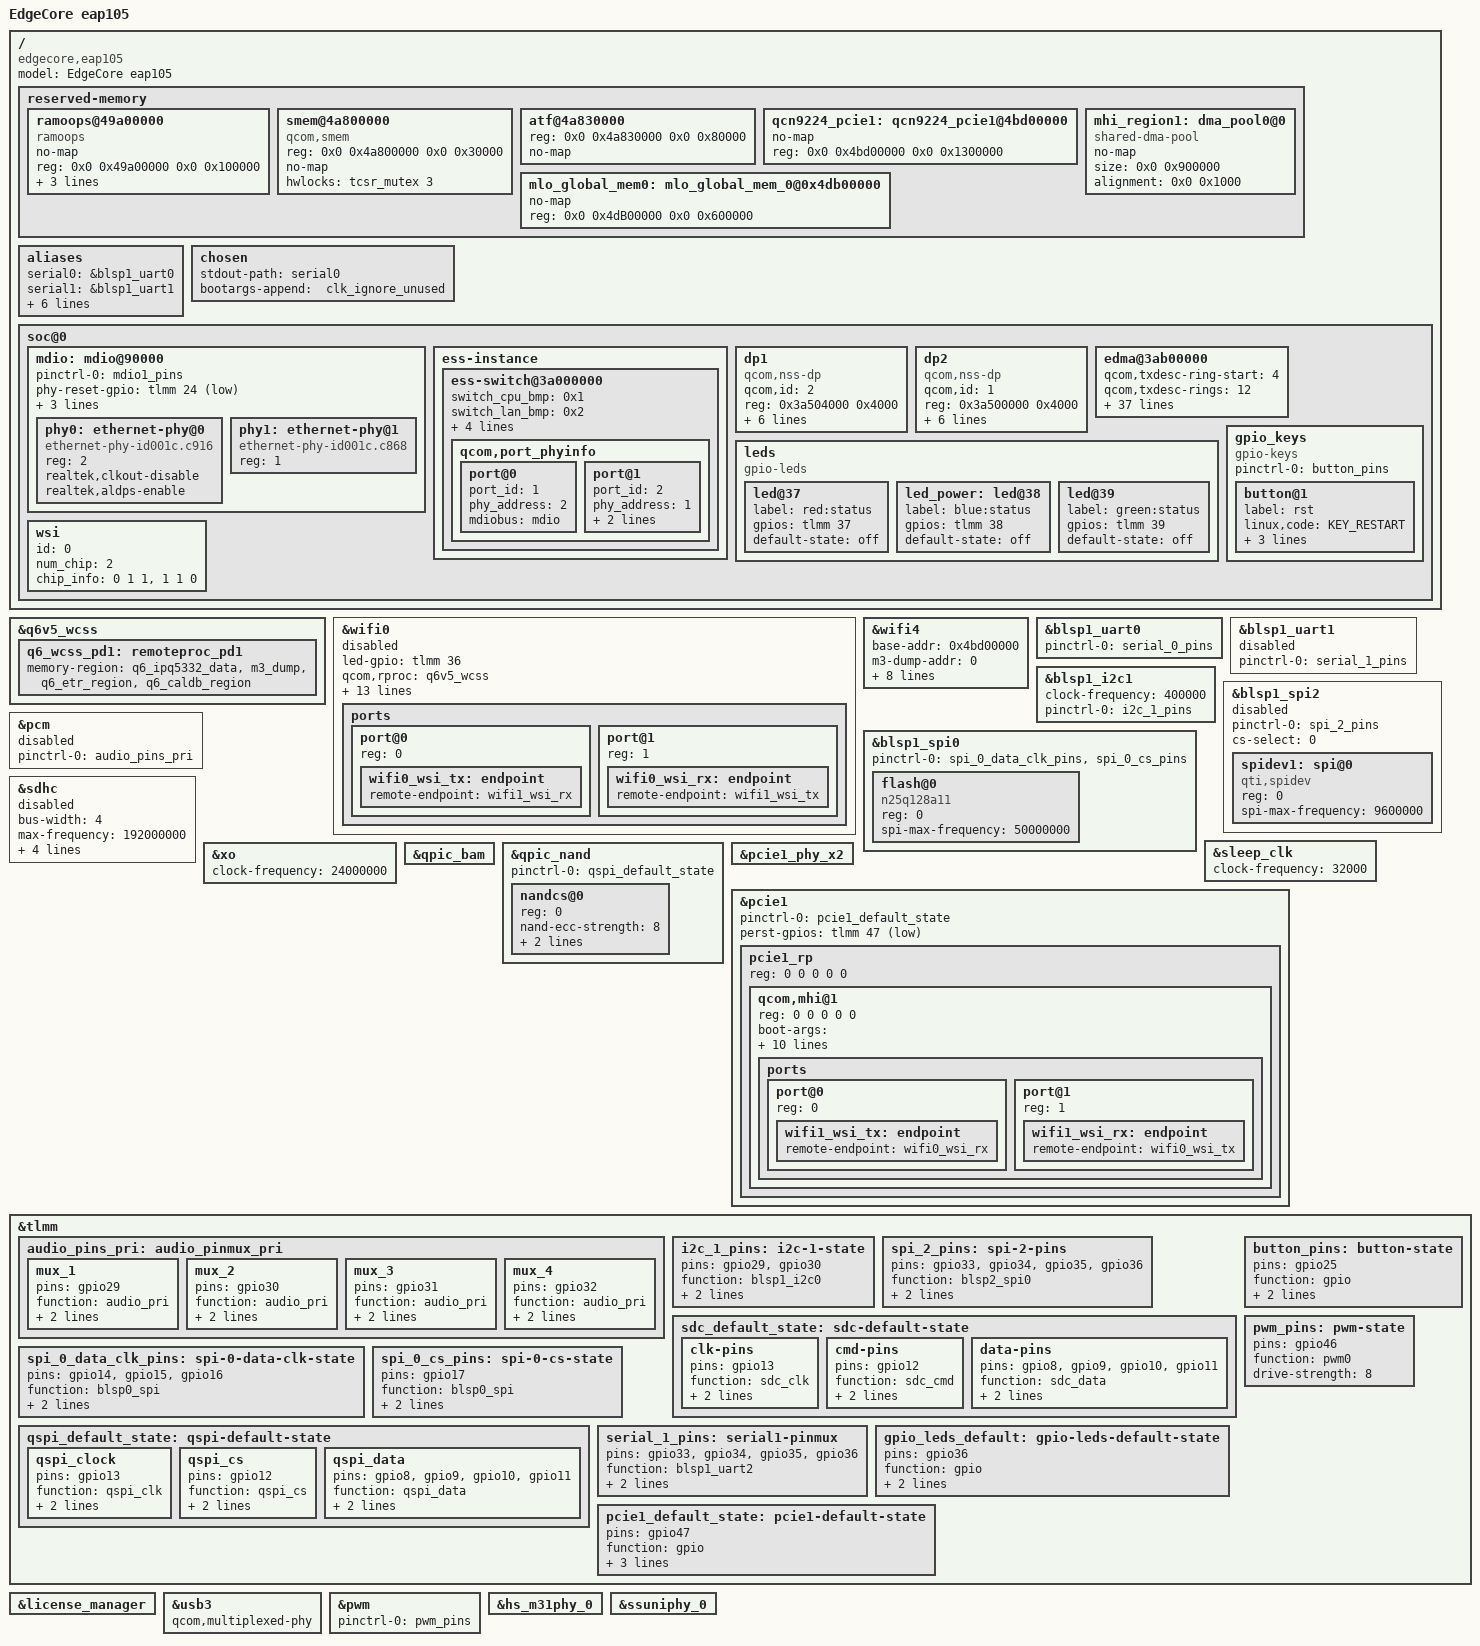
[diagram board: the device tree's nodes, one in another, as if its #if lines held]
// SPDX-License-Identifier: (GPL-2.0+ OR BSD-3-Clause)
/*
 * IPQ5332 RDP468 board device tree source
 *
 * Copyright (c) 2020-2021 The Linux Foundation. All rights reserved.
 * Copyright (c) 2022-2025 Qualcomm Innovation Center, Inc. All rights reserved.
 */

/dts-v1/;

#define __RPROC_DISABLE_MPD_SUPPORT__

#include <dt-bindings/gpio/gpio.h>
#include <dt-bindings/input/input.h>
#include <dt-bindings/leds/common.h>
#include "ipq5332.dtsi"
#include "ipq5332-default-memory.dtsi"

/ {
	model = "EdgeCore eap105";
	compatible = "edgecore,eap105", "qcom,ipq5332-ap-mi01.6", "qcom,ipq5332";

	reserved-memory {
		#address-cells = <2>;
		#size-cells = <2>;
		ranges;

		ramoops@49a00000 {
			compatible = "ramoops";
			no-map;
			reg = <0x0 0x49a00000 0x0 0x100000>;
			record-size = <0x50000>;
			console-size = <0x50000>;
			pmsg-size = <0x50000>;
		};
	};

	aliases {
		serial0 = &blsp1_uart0;
		serial1 = &blsp1_uart1;
		ethernet0 = "/soc/dp1";
		ethernet1 = "/soc/dp2";
		led-boot = &led_power;
		led-failsafe = &led_power;
		led-running = &led_power;
		led-upgrade = &led_power;
	};

	chosen {
		stdout-path = "serial0";
		bootargs-append = " clk_ignore_unused";
	};

#if defined(__IPQ_MEM_PROFILE_256_MB__)
	/*	  256MB Profile for IPQ5322 + QCN9224
	 * +=========+==============+========================+
	 * |        |              |                         |
	 * | Region | Start Offset |          Size           |
	 * |        |              |                         |
	 * +--------+--------------+-------------------------+
	 * |  SMEM  |  0x4A800000  |          192KB          |
	 * +--------+--------------+-------------------------+
	 * |  ATF   |  0x4A830000  |          512KB          |
	 * +--------+--------------+-------------------------+
	 * |       320 KB not-reserved, used by linux        |
	 * +--------+--------------+-------------------------+
	 * |  WKK0  |  0x4BD00000  |          19MB           |
	 * +--------+--------------+-------------------------+
	 * |       11 MB not-reserved, used by linux         |
	 * +--------+--------------+-------------------------+
	 * |  MLO   |  0x4DB00000  |           5MB           |
	 * +--------+--------------+-------------------------+
	 * |  MHI0  |    DYNAMIC   |           9MB           |
	 * +=================================================+
	 * |                                                 |
	 * |                                                 |
	 * |            Rest of memory for Linux             |
	 * |                                                 |
	 * |                                                 |
	 * +=================================================+
	 */

	reserved-memory {
		/delete-node/ bootloader@4a300000;
		/delete-node/ sbl@4a500000;

		smem@4a800000 {
			compatible = "qcom,smem";
			reg = <0x0 0x4a800000 0x0 0x30000>;
			no-map;
			hwlocks = <&tcsr_mutex 3>;
		};

		atf@4a830000 {
			reg = <0x0 0x4a830000 0x0 0x80000>;
			no-map;
		};

		qcn9224_pcie1: qcn9224_pcie1@4bd00000 {
			no-map;
			reg = <0x0 0x4bd00000 0x0 0x1300000>;
		};

		mlo_global_mem0: mlo_global_mem_0@0x4db00000 {
			no-map;
			reg = <0x0 0x4dB00000 0x0 0x600000>;
		};

		mhi_region1: dma_pool0@0 {
			compatible = "shared-dma-pool";
			no-map;
			size = <0x0 0x900000>;
			alignment = <0x0 0x1000>;
		};
	};
#endif

	soc@0 {
		mdio:mdio@90000 {
			pinctrl-0 = <&mdio1_pins>;
			pinctrl-names = "default";
			phy-reset-gpio = <&tlmm 24 GPIO_ACTIVE_LOW>;
			phyaddr_fixup = <0xC90F018>;
			uniphyaddr_fixup = <0xC90F014>;
			mdio_clk_fixup; /* MDIO clock sequence fix up flag */
			status = "okay";

			phy0: ethernet-phy@0 {
				reg = <2>;
				compatible = "ethernet-phy-id001c.c916";
				realtek,clkout-disable;
				realtek,aldps-enable;
			};

			phy1: ethernet-phy@1 {
				reg = <1>;
				compatible = "ethernet-phy-id001c.c868";
			};
		};

		ess-instance {
			ess-switch@3a000000 {
				switch_cpu_bmp = <0x1>;  /* cpu port bitmap */
				switch_lan_bmp = <0x2>; /* lan port bitmap */
				switch_wan_bmp = <0x4>; /* wan port bitmap */
				switch_mac_mode = <0xf>; /* mac mode for uniphy instance0*/
				switch_mac_mode1 = <0xd>; /* mac mode for uniphy instance1*/
				switch_mac_mode2 = <0xff>; /* mac mode for uniphy instance2*/

				qcom,port_phyinfo {
					port@0 {
						port_id = <1>;
						phy_address = <2>;
						mdiobus = <&mdio>;
					};
					port@1 {
						port_id = <2>;
						phy_address = <1>;
						mdiobus = <&mdio>;
						ethernet-phy-ieee802.3-c45;
					};
				};
			};
		};

		dp1 {
			device_type = "network";
			compatible = "qcom,nss-dp";
			qcom,id = <2>;
			reg = <0x3a504000 0x4000>;
			qcom,mactype = <1>;
			local-mac-address = [000000000000];
			mdio-bus = <&mdio>;
			qcom,phy-mdio-addr = <1>;
			qcom,link-poll = <1>;
			phy-mode = "sgmii";
		};

		dp2 {
			device_type = "network";
			compatible = "qcom,nss-dp";
			qcom,id = <1>;
			reg = <0x3a500000 0x4000>;
			qcom,mactype = <0>;
			local-mac-address = [000000000000];
			mdio-bus = <&mdio>;
			qcom,phy-mdio-addr = <2>;
			qcom,link-poll = <1>;
			phy-mode = "sgmii";
		};

		/* EDMA host driver configuration for the board */
		edma@3ab00000 {
			qcom,txdesc-ring-start = <4>;		/* Tx desc ring start ID */
			qcom,txdesc-rings = <12>;		/* Total number of Tx desc rings to be provisioned */
			qcom,mht-txdesc-rings = <8>;            /* Extra Tx desc rings to be provisioned for MHT SW ports */
			qcom,txcmpl-ring-start = <4>;		/* Tx complete ring start ID */
			qcom,txcmpl-rings = <12>;		/* Total number of Tx complete rings to be provisioned */
			qcom,mht-txcmpl-rings = <8>;            /* Extra Tx complete rings to be provisioned for mht sw ports. */
			qcom,rxfill-ring-start = <4>;		/* Rx fill ring start ID */
			qcom,rxfill-rings = <4>;		/* Total number of Rx fill rings to be provisioned */
			qcom,rxdesc-ring-start = <12>;		/* Rx desc ring start ID */
			qcom,rxdesc-rings = <4>;		/* Total number of Rx desc rings to be provisioned */
			qcom,rx-page-mode = <0>;		/* Rx fill ring page mode */
			qcom,tx-map-priority-level = <1>;	/* Tx priority level per port */
			qcom,rx-map-priority-level = <1>;	/* Rx priority level per core */
			qcom,num_loopback_rings = <1>;
			qcom,txdesc_loopback_ring_id = <0>;
			qcom,txcmpl_loopback_ring_id = <0>;
			qcom,rxfill_loopback_ring_id = <0>;
			qcom,rxdesc_loopback_ring_id = <0>;
			qcom,loopback_queue_base = <56>;
			qcom,loopback_num_queues = <8>;
			qcom,ppeds-num = <2>;			/* Number of PPEDS nodes */
			/* PPE-DS node format: <Rx-fill Tx-cmpl Rx Tx Queue-base Queue-count> */
			qcom,ppeds-map = <1 1 1 1 32 8>,	/* PPEDS Node#0 ring and queue map */
					<2 2 2 2 40 8>;		/* PPEDS Node#1 ring and queue map */
			qcom,txdesc-map = <8 9 10 11>,		/* Port0 per-core Tx ring map */
					<12 13 14 15>,        /* MHT-Port1 per-core Tx ring map */
					<4 5 6 7>,            /* MHT-Port2 per-core Tx ring map/packets from  vp*/
					<16 17 18 19>,        /* MHT-Port3 per-core Tx ring map */
					<20 21 22 23>;        /* MHT-Port4 per-core Tx ring map */
			qcom,txdesc-fc-grp-map = <1 2 3 4 5>;   /* Per GMAC flow control group map */
			qcom,rxfill-map = <4 5 6 7>;		/* Per-core Rx fill ring map */
			qcom,rxdesc-map = <12 13 14 15>;	/* Per-core Rx desc ring map */
			qcom,rx-queue-start = <0>;		/* Rx queue start */
			qcom,rx-ring-queue-map = <0 8 16 24>,	/* Priority 0 queues per-core Rx ring map */
						<1 9 17 25>,	/* Priority 1 queues per-core Rx ring map */
						<2 10 18 26>,	/* Priority 2 queues per-core Rx ring map */
						<3 11 19 27>,	/* Priority 3 queues per-core Rx ring map */
						<4 12 20 28>,	/* Priority 4 queues per-core Rx ring map */
						<5 13 21 29>,	/* Priority 5 queues per-core Rx ring map */
						<6 14 22 30>,	/* Priority 6 queues per-core Rx ring map */
						<7 15 23 31>;	/* Priority 7 queues per-core Rx ring map */
			interrupts = <0 163 4>,			/* Tx complete ring id #4 IRQ info */
				   <0 164 4>,			/* Tx complete ring id #5 IRQ info */
				   <0 165 4>,			/* Tx complete ring id #6 IRQ info */
				   <0 166 4>,			/* Tx complete ring id #7 IRQ info */
				   <0 167 4>,			/* Tx complete ring id #8 IRQ info */
				   <0 168 4>,			/* Tx complete ring id #9 IRQ info */
				   <0 169 4>,			/* Tx complete ring id #10 IRQ info */
				   <0 170 4>,			/* Tx complete ring id #11 IRQ info */
				   <0 171 4>,			/* Tx complete ring id #12 IRQ info */
				   <0 172 4>,			/* Tx complete ring id #13 IRQ info */
				   <0 173 4>,			/* Tx complete ring id #14 IRQ info */
				   <0 174 4>,			/* Tx complete ring id #15 IRQ info */
				   <0 139 4>,			/* Rx desc ring id #12 IRQ info */
				   <0 140 4>,			/* Rx desc ring id #13 IRQ info */
				   <0 141 4>,			/* Rx desc ring id #14 IRQ info */
				   <0 142 4>,			/* Rx desc ring id #15 IRQ info */
				   <0 191 4>,			/* Misc error IRQ info */
				   <0 155 4>,			/* RxFill ring id #4 IRQ info */
				   <0 156 4>,			/* RxFill ring id #5 IRQ info */
				   <0 157 4>,			/* RxFill ring id #6 IRQ info */
				   <0 158 4>,			/* RxFill ring id #7 IRQ info */
				<0 160 4>,			/* PPEDS Node #1(TxComp ring id #1) TxComplete IRQ info */
				<0 128 4>,			/* PPEDS Node #1(Rx Desc ring id #1) Rx Desc IRQ info */
				<0 152 4>,			/* PPEDS Node #1(RxFill Desc ring id #1) Rx Fill IRQ info */
				<0 161 4>,			/* PPEDS Node #2(TxComp ring id #2) TxComplete IRQ info */
				<0 129 4>,			/* PPEDS Node #2(Rx Desc ring id #2) Rx Desc IRQ info */
				<0 153 4>,                      /* PPEDS Node #2(RxFill Desc ring id #2) Rx Fill IRQ info */
				<0 175 4>,                   /* MHT port Tx complete ring id #16 IRQ info */
				<0 176 4>,                   /* MHT port Tx complete ring id #17 IRQ info */
				<0 177 4>,                   /* MHT port Tx complete ring id #18 IRQ info */
				<0 178 4>,                   /* MHT port Tx complete ring id #19 IRQ info */
				<0 179 4>,                   /* MHT port Tx complete ring id #20 IRQ info */
				<0 180 4>,                   /* MHT port Tx complete ring id #21 IRQ info */
				<0 181 4>,                   /* MHT port Tx complete ring id #22 IRQ info */
				<0 182 4>;                   /* MHT port Tx complete ring id #23 IRQ info */
		};

		leds {
                        compatible = "gpio-leds";

                        led@37 {
                                label = "red:status";
                                gpios = <&tlmm 37 GPIO_ACTIVE_HIGH>;
                                default-state = "off";
                        };
                        led_power: led@38 {
                                label = "blue:status";
                                gpios = <&tlmm 38 GPIO_ACTIVE_HIGH>;
                                default-state = "off";
                        };
                        led@39 {
                                label = "green:status";
                                gpios = <&tlmm 39 GPIO_ACTIVE_HIGH>;
                                default-state = "off";
                        };
                };

		gpio_keys {
			compatible = "gpio-keys";
			pinctrl-0 = <&button_pins>;
			pinctrl-names = "default";
			button@1 {
				label = "rst";
				linux,code = <KEY_RESTART>;
				gpios = <&tlmm 25 GPIO_ACTIVE_LOW>;
				linux,input-type = <1>;
				debounce-interval = <60>;
			};
		};

		wsi: wsi {
			id = <0>;
			num_chip = <2>;
			status = "okay";
			chip_info = <0 1 1>,
				    <1 1 0>;
		};
	};
};

&q6v5_wcss {
#ifndef __IPQ_MEM_PROFILE_256_MB__
	q6_wcss_pd1: remoteproc_pd1 {
		memory-region = <&q6_ipq5332_data>,
				<&m3_dump>,
				<&q6_etr_region>,
				<&q6_caldb_region>;
	};
#else
	status = "disabled";
	/delete-property/ memory-region;
	q6_wcss_pd1: remoteproc_pd1 {
		     status = "disabled";
	};
#endif
};

&wifi0 {
	led-gpio = <&tlmm 36 GPIO_ACTIVE_HIGH>;
#if defined(__RPROC_DISABLE_MPD_SUPPORT__)
	qcom,rproc = <&q6v5_wcss>;
	dump-region = <&q6_ipq5332_data>,
		<&m3_dump>,
		<&q6_etr_region>,
		<&q6_caldb_region>;
#else
	qcom,rproc = <&q6_wcss_pd1>;
	qcom,rproc_rpd = <&q6v5_wcss>;
	qcom,multipd_arch;
#endif
	qcom,userpd-subsys-name = "q6v5_wcss_userpd1";

#ifndef __IPQ_MEM_PROFILE_256_MB__
	memory-region = <&q6_region>, <&q6_region>, <&q6_ipq5332_data>, <&m3_dump>,
			<&mlo_global_mem0>,<&q6_etr_region>;
	memory-region-names = "q6-region", "q6region-1", "host-ddr-mem", "m3-dump",
			      "mlo-global-mem", "q6-etr-dump";
#endif
	qcom,wsi = <&wsi>;
	qcom,wsi_index = <0>;
	qcom,board_id = <0x16>;
	status = "okay";
	qcom,wsi-controller;
	ports {
		#address-cells = <1>;
		#size-cells = <0>;

		port@0 {
			reg = <0>;

			wifi0_wsi_tx: endpoint {
				remote-endpoint = <&wifi1_wsi_rx>;
			};
		};

		port@1 {
			reg = <1>;

			wifi0_wsi_rx: endpoint {
				remote-endpoint = <&wifi1_wsi_tx>;
			};
		};
	};
};
#ifdef __IPQ_MEM_PROFILE_256_MB__
&wifi0 {
	status = "disabled";
};
#endif

&mhi_region1 {
	status = "okay";
};

&qcn9224_pcie1 {
	status = "okay";
};

/* QCN9224 5G+6G */
&wifi4 {
#if defined(__IPQ_MEM_PROFILE_256_MB__)
	/* qcn9224 tgt-mem-mode=2 layout - 11MB
	 * +=========+==============+=========+
	 * |  Region | Start Offset |   Size  |
	 * +---------+--------------+---------+
	 * | HREMOTE |  0x4bd00000  |   14MB  |
	 * +---------+--------------+---------+
	 * |Pageable |  0x4cb00000  |   5MB   |
	 * +==================================+
	 */
	base-addr = <0x4bd00000>;
	m3-dump-addr = <0>;
	pageable-addr = <0x4cb00000>;
	hremote-size = <0xE00000>;
	pageable-size = <0x500000>;
	caldb-size = <0>;
	tgt-mem-mode = <0x2>;
#endif
	hremote_node = <&qcn9224_pcie1>;
	board_id = <0x1019>;
	node_id = <0x1>;
	status = "okay";
};

&blsp1_uart0 {
	pinctrl-0 = <&serial_0_pins>;
	pinctrl-names = "default";
	status = "okay";
};

&blsp1_uart1 {
	pinctrl-0 = <&serial_1_pins>;
	pinctrl-names = "default";
	status = "disabled";
};

&blsp1_i2c1 {
	clock-frequency  = <400000>;
	pinctrl-0 = <&i2c_1_pins>;
	pinctrl-names = "default";
};

&blsp1_spi0 {
	pinctrl-0 = <&spi_0_data_clk_pins &spi_0_cs_pins>;
	pinctrl-names = "default";
	status = "okay";

	flash@0 {
		compatible = "n25q128a11"; 
		//, "jedec,spi-nor";
		reg = <0>;
		#address-cells = <1>;
		#size-cells = <1>;
		spi-max-frequency = <50000000>;
	};
};

&blsp1_spi2 {
	pinctrl-0 = <&spi_2_pins>;
	pinctrl-names = "default";
	cs-select = <0>;
	status = "disabled";

	spidev1: spi@0 {
		compatible = "qti,spidev";
		reg = <0>;
		spi-max-frequency = <9600000>;
	};
};

&pcm {
	pinctrl-0 = <&audio_pins_pri>;
	pinctrl-names = "primary";
	status = "disabled";
};

&sdhc {
	bus-width = <4>;
	max-frequency = <192000000>;
	mmc-ddr-1_8v;
	mmc-hs200-1_8v;
	non-removable;
	pinctrl-0 = <&sdc_default_state>;
	pinctrl-names = "default";
	status = "disabled";
};

&sleep_clk {
	clock-frequency = <32000>;
};

&xo {
	clock-frequency = <24000000>;
};

&qpic_bam {
	status = "okay";
};

&qpic_nand {
	pinctrl-0 = <&qspi_default_state>;
	pinctrl-names = "default";
	status = "okay";

	nandcs@0 {
		reg = <0>;
		#address-cells = <1>;
		#size-cells = <1>;

		nand-ecc-strength = <8>;
		nand-ecc-step-size = <512>;
		nand-bus-width = <8>;
	};
};

&pcie1_phy_x2 {
	status = "okay";
};

&pcie1 {
	pinctrl-0 = <&pcie1_default_state>;
	pinctrl-names = "default";
	perst-gpios = <&tlmm 47 GPIO_ACTIVE_LOW>;
	status = "okay";

	pcie1_rp {
		reg = <0 0 0 0 0>;

		qcom,mhi@1 {
			reg = <0 0 0 0 0>;
			boot-args = <0x2 0x4 0x34 0x3 0x0 0x0     /* MX Rail, GPIO52, Drive strength 0x3 */
					0x4 0x4 0x18 0x3 0x0 0x0  /* RFA1p2 Rail, GPIO24, Drive strength 0x3 */
					0x0 0x4 0x0 0x0 0x0 0x0>; /* End of arguments */
			memory-region = <&qcn9224_pcie1>, <&mhi_region1>, <&mlo_global_mem0>;
			memory-region-names = "host-ddr-mem", "mhi-region", "mlo-global-mem";
			qcom,wsi = <&wsi>;
			qcom,wsi_index = <1>;
			qcom,early_cal_enabled = "supported";
			qcom,caldata_offset = <0x58800>;
			qcom,board_id = <0x1019>;
			ports {
				#address-cells = <1>;
				#size-cells = <0>;

				port@0 {
					reg = <0>;

					wifi1_wsi_tx: endpoint {
						remote-endpoint = <&wifi0_wsi_rx>;
					};
				};

				port@1 {
					reg = <1>;

					wifi1_wsi_rx: endpoint {
						remote-endpoint = <&wifi0_wsi_tx>;
					};
				};
			};
		};
	};
};

/* PINCTRL */

&tlmm {

	audio_pins_pri: audio_pinmux_pri {
		mux_1 {
			pins = "gpio29";
			function = "audio_pri";
			drive-strength = <8>;
			bias-pull-down;
		};

		mux_2 {
			pins = "gpio30";
			function = "audio_pri";
			drive-strength = <8>;
			bias-pull-down;
		};

		mux_3 {
			pins = "gpio31";
			function = "audio_pri";
			drive-strength = <4>;
			bias-pull-down;
		};

		mux_4 {
			pins = "gpio32";
			function = "audio_pri";
			drive-strength = <4>;
			bias-pull-down;
		};
	};

	i2c_1_pins: i2c-1-state {
		pins = "gpio29", "gpio30";
		function = "blsp1_i2c0";
		drive-strength = <8>;
		bias-pull-up;
	};

	spi_2_pins: spi-2-pins {
		pins = "gpio33", "gpio34", "gpio35", "gpio36";
		function = "blsp2_spi0";
		drive-strength = <8>;
		bias-pull-down;
	};

	sdc_default_state: sdc-default-state {
		clk-pins {
			pins = "gpio13";
			function = "sdc_clk";
			drive-strength = <8>;
			bias-disable;
		};

		cmd-pins {
			pins = "gpio12";
			function = "sdc_cmd";
			drive-strength = <8>;
			bias-pull-up;
		};

		data-pins {
			pins = "gpio8", "gpio9", "gpio10", "gpio11";
			function = "sdc_data";
			drive-strength = <8>;
			bias-pull-up;
		};
	};

	spi_0_data_clk_pins: spi-0-data-clk-state {
		pins = "gpio14", "gpio15", "gpio16";
		function = "blsp0_spi";
		drive-strength = <2>;
		bias-pull-down;
	};

	spi_0_cs_pins: spi-0-cs-state {
		pins = "gpio17";
		function = "blsp0_spi";
		drive-strength = <2>;
		bias-pull-up;
	};

	qspi_default_state: qspi-default-state {
		qspi_clock {
			pins = "gpio13";
			function = "qspi_clk";
			drive-strength = <8>;
			bias-pull-down;
		};

		qspi_cs {
			pins = "gpio12";
			function = "qspi_cs";
			drive-strength = <8>;
			bias-pull-up;
		};

		qspi_data {
			pins = "gpio8", "gpio9", "gpio10", "gpio11";
			function = "qspi_data";
			drive-strength = <8>;
			bias-pull-down;
		};
	};

	serial_1_pins: serial1-pinmux {
		pins = "gpio33", "gpio34", "gpio35", "gpio36";
		function = "blsp1_uart2";
		drive-strength = <8>;
		bias-pull-up;
	};

	gpio_leds_default: gpio-leds-default-state {
		pins = "gpio36";
		function = "gpio";
		drive-strength = <8>;
		bias-pull-down;
	};

	button_pins: button-state {
		pins = "gpio25";
		function = "gpio";
		drive-strength = <8>;
		bias-pull-up;
	};

	pwm_pins: pwm-state {
		pins = "gpio46";
		function = "pwm0";
		drive-strength = <8>;
	};

	pcie1_default_state: pcie1-default-state {
		pins = "gpio47";
		function = "gpio";
		drive-strength = <8>;
		bias-pull-up;
		output-low;
	};
};

&license_manager {
	status = "okay";
};

&usb3 {
	qcom,multiplexed-phy;
	status = "okay";
};

&pwm {
	pinctrl-0 = <&pwm_pins>;
	pinctrl-names = "default";
	status = "okay";
};

&hs_m31phy_0 {
	status = "okay";
};

&ssuniphy_0 {
	status = "okay";
};
